# max78000 register map
Vendor: Maxim-Integrated; Series: ARMCM4; File version: 1.1
CPU: CM4 r2p1, little endian, MPU, FPU, 3 interrupt priority bits
Registers are 32-bit, read-write, reset 0x0 unless marked. A register's access mark holds for its fields unless they carry their own. Offsets are from the block's base; [hi:lo] are bit positions; {n}, {i} and the like mark numbered series; 'fields as' and 'values as' point back to an identical list.

## ADC — 10-bit Analog to Digital Converter
Base 0x40034000
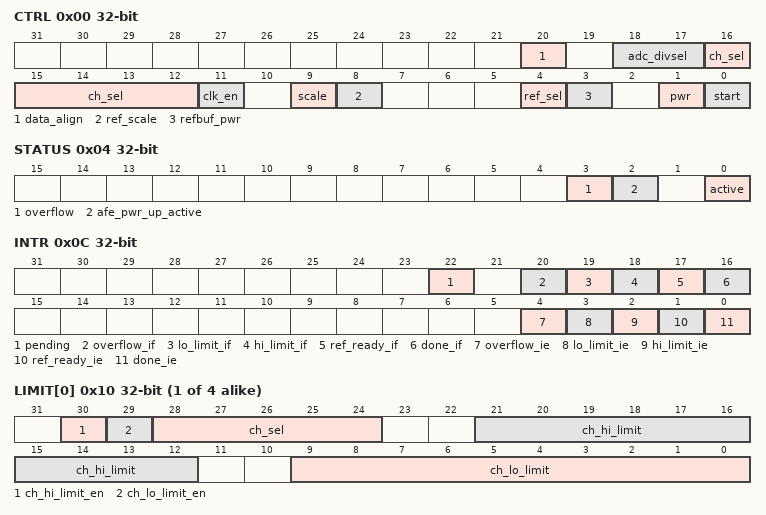
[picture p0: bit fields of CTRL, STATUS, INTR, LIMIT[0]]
0x00 CTRL — ADC Control
  [20] data_align — ADC Data Alignment Select
  [18:17] adc_divsel — Scales the external inputs, all inputs are scaled the same
    {v}=DIV{v+1} (v=0..3)
  [16:12] ch_sel — ADC Channel Select
    {v}=AIN{v} (v=0..7); 8=VcoreA; 9=VcoreB; 10=Vrxout; 11=Vtxout; 12=VddA; 13=VddB/4; 14=Vddio/4; 15=Vddioh/4; 16=VregI/4
  [11] clk_en — ADC Clock Enable
  [9] scale — ADC Scale
  [8] ref_scale — ADC Reference Scale
  [4] ref_sel — ADC Reference Select
  [3] refbuf_pwr — ADC Reference Buffer Power Up
  [1] pwr — ADC Power Up
  [0] start — Start ADC Conversion
0x04 STATUS — ADC Status
  [3] overflow ro — ADC Overflow
  [2] afe_pwr_up_active ro — AFE Power Up Delay Active
  [0] active ro — ADC Conversion In Progress
0x08 DATA — ADC Output Data
  [15:0] adc_data ro — ADC Converted Sample Data Output
0x0C INTR — ADC Interrupt Control Register
  [22] pending ro — ADC Interrupt Pending Status
  [20] overflow_if write-1-clears — ADC Overflow Interrupt Flag
  [19] lo_limit_if write-1-clears — ADC Lo Limit Monitor Interrupt Flag
  [18] hi_limit_if write-1-clears — ADC Hi Limit Monitor Interrupt Flag
  [17] ref_ready_if write-1-clears — ADC Reference Ready Interrupt Flag
  [16] done_if write-1-clears — ADC Done Interrupt Flag
  [4] overflow_ie — ADC Overflow Interrupt Enable
  [3] lo_limit_ie — ADC Lo Limit Monitor Interrupt Enable
  [2] hi_limit_ie — ADC Hi Limit Monitor Interrupt Enable
  [1] ref_ready_ie — ADC Reference Ready Interrupt Enable
  [0] done_ie — ADC Done Interrupt Enable
{0x10+4i} LIMIT[{i}] (i=0..3) — ADC Limit
  [30] ch_hi_limit_en — High Limit Monitoring Enable
  [29] ch_lo_limit_en — Low Limit Monitoring Enable
  [28:24] ch_sel — ADC Channel Select
  [21:12] ch_hi_limit — High Limit Threshold
  [9:0] ch_lo_limit — Low Limit Threshold

## AES — AES Keys.
Base 0x40007400
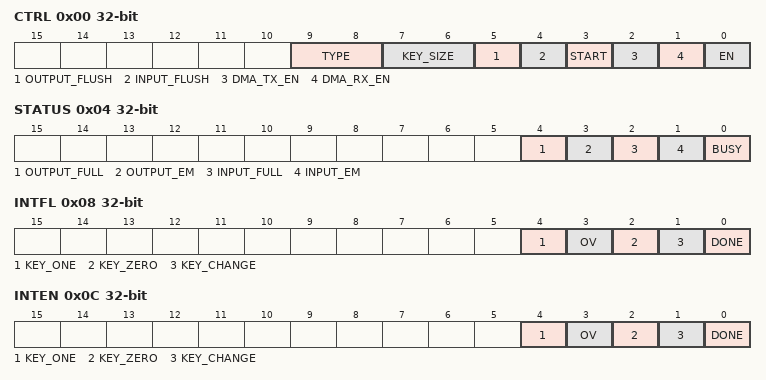
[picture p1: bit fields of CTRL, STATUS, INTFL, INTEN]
0x00 CTRL — AES Control Register
  [9:8] TYPE — Encryption Type Selection
  [7:6] KEY_SIZE — Encryption Key Size
    0=AES128 (128 Bits.); 1=AES192 (192 Bits.); 2=AES256 (256 Bits.)
  [5] OUTPUT_FLUSH — Flush the data output FIFO
  [4] INPUT_FLUSH — Flush the data input FIFO
  [3] START — Start AES Calculation
  [2] DMA_TX_EN — DMA Request To Write Data Input FIFO
  [1] DMA_RX_EN — DMA Request To Read Data Output FIFO
  [0] EN — AES Enable
0x04 STATUS — AES Status Register
  [4] OUTPUT_FULL — Data output FIFO full status
  [3] OUTPUT_EM — Data output FIFO empty status
  [2] INPUT_FULL — Data input FIFO full status
  [1] INPUT_EM — Data input FIFO empty status
  [0] BUSY — AES Busy Status
0x08 INTFL — AES Interrupt Flag Register
  [4] KEY_ONE
  [3] OV — Data Output FIFO Overrun Interrupt
  [2] KEY_ZERO — External AES Key Zero Interrupt
  [1] KEY_CHANGE — External AES Key Changed Interrupt
  [0] DONE — AES Done Interrupt
0x0C INTEN — AES Interrupt Enable Register
  [4] KEY_ONE
  [3] OV — Data Output FIFO Overrun Interrupt Enable
  [2] KEY_ZERO — External AES Key Zero Interrupt Enable
  [1] KEY_CHANGE — External AES Key Changed Interrupt Enable
  [0] DONE — AES Done Interrupt Enable
0x10 FIFO — AES Data Register
  [0] DATA — AES FIFO

## AESKEYS — AES Key Registers.
Base 0x40007800
{0x0+4i} KEY{i} (i=0..7) — AES Key {i}.

## CAMERAIF — Parallel Camera Interface.
Base 0x4000E000
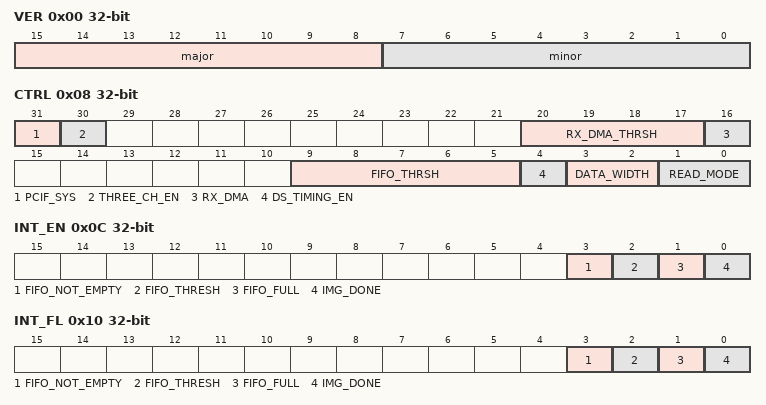
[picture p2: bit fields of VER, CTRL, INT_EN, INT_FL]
0x00 VER — Hardware Version.
  [15:8] major — Major Version Number.
  [7:0] minor — Minor Version Number.
0x04 FIFO_SIZE — FIFO Depth.
  [7:0] fifo_size
0x08 CTRL — Control Register.
  [31] PCIF_SYS — PCIF Control.
    0=dis (PCIF disabled.); 1=en (PCIF enabled.)
  [30] THREE_CH_EN — Three-channel mode enable.
  [20:17] RX_DMA_THRSH — DMA Threshold.
  [16] RX_DMA — DMA Enable.
    0=dis (DMA disabled.); 1=en (DMA enabled.)
  [9:5] FIFO_THRSH — Data FIFO Threshold.
  [4] DS_TIMING_EN — DS Timing Enable.
    0=dis (Timing from VSYNC and HSYNC.); 1=en (Timing embedded in data using SAV and EAV codes.)
  [3:2] DATA_WIDTH
    0=8bit; 1=10bit; 2=12bit
  [1:0] READ_MODE
    0=dis (Camera Interface Disabled.); 1=single_img (Single Image Capture.); 2=Continuous Image Capture
0x0C INT_EN — Interrupt Enable Register.
  [3] FIFO_NOT_EMPTY
  [2] FIFO_THRESH — FIFO Threshold Level Met.
  [1] FIFO_FULL
  [0] IMG_DONE — Image Done.
0x10 INT_FL — Interrupt Flag Register.
  fields as INT_EN
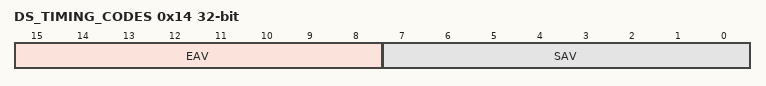
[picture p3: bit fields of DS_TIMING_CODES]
0x14 DS_TIMING_CODES — DS Timing Code Register.
  [15:8] EAV — End Active Video Code.
  [7:0] SAV — Start Active Video Code.
0x30 FIFO_DATA
  [31:0] DATA — Data from FIFO to be read by DMA.
